# MK30D10 register map
Vendor: Freescale Semiconductor, Inc.; Series: Kinetis_K; File version: 1.6
CPU: CM4 r0p1, little endian, no MPU, no FPU, VTOR, 4 interrupt priority bits
Registers are 32-bit, read-write, reset 0x0 unless marked. A register's access mark holds for its fields unless they carry their own. Offsets are from the block's base; [hi:lo] are bit positions; {n}, {i} and the like mark numbered series; 'fields as' and 'values as' point back to an identical list.

## DAC0 — 12-Bit Digital-to-Analog Converter
Base 0x400CC000; register names take the prefix DAC0_
{0x0+2i} DAT{i}L (i=0..15) 8-bit — DAC Data Low Register
  [7:0] DATA0 — When the DAC buffer is not enabled, DATA[11:0] controls the output voltage based on the following formula: V out = V in * (1 + DACDAT0[11:0])/4096 When the DAC buffer is enabled, DATA is mapped to the 16-word buffer
{0x1+2i} DAT{i}H (i=0..15) 8-bit — DAC Data High Register
  [3:0] DATA1 — When the DAC Buffer is not enabled, DATA[11:0] controls the output voltage based on the following formula
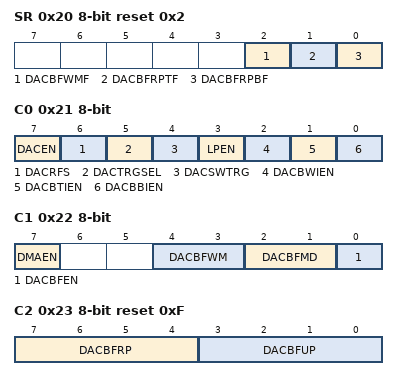
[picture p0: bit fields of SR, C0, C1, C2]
0x20 SR 8-bit reset 0x2 — DAC Status Register
  [2] DACBFWMF — DAC Buffer Watermark Flag
    0=The DAC buffer read pointer has not reached the watermark level; 1=The DAC buffer read pointer has reached the watermark level
  [1] DACBFRPTF — DAC Buffer Read Pointer Top Position Flag
    0=The DAC buffer read pointer is not zero; 1=The DAC buffer read pointer is zero
  [0] DACBFRPBF — DAC Buffer Read Pointer Bottom Position Flag
    0=The DAC buffer read pointer is not equal to C2[DACBFUP]; 1=The DAC buffer read pointer is equal to C2[DACBFUP]
0x21 C0 8-bit — DAC Control Register
  [7] DACEN — DAC Enable
    0=The DAC system is disabled; 1=The DAC system is enabled
  [6] DACRFS — DAC Reference Select
    0=The DAC selects DACREF_1 as the reference voltage; 1=The DAC selects DACREF_2 as the reference voltage
  [5] DACTRGSEL — DAC Trigger Select
    0=The DAC hardware trigger is selected; 1=The DAC software trigger is selected
  [4] DACSWTRG wo — DAC Software Trigger
    0=The DAC soft trigger is not valid; 1=The DAC soft trigger is valid
  [3] LPEN — DAC Low Power Control
    0=High-Power mode; 1=Low-Power mode
  [2] DACBWIEN — DAC Buffer Watermark Interrupt Enable
    0=The DAC buffer watermark interrupt is disabled; 1=The DAC buffer watermark interrupt is enabled
  [1] DACBTIEN — DAC Buffer Read Pointer Top Flag Interrupt Enable
    0=The DAC buffer read pointer top flag interrupt is disabled; 1=The DAC buffer read pointer top flag interrupt is enabled
  [0] DACBBIEN — DAC Buffer Read Pointer Bottom Flag Interrupt Enable
    0=The DAC buffer read pointer bottom flag interrupt is disabled; 1=The DAC buffer read pointer bottom flag interrupt is enabled
0x22 C1 8-bit — DAC Control Register 1
  [7] DMAEN — DMA Enable Select
    0=DMA is disabled; 1=DMA is enabled. When DMA is enabled, the DMA request will be generated by original interrupts. The interrupts will not be presented on this module at the same time.
  [4:3] DACBFWM — DAC Buffer Watermark Select
    0=1 word; 1=2 words; 2=3 words; 3=4 words
  [2:1] DACBFMD — DAC Buffer Work Mode Select
    0=Normal mode; 1=Swing mode; 2=One-Time Scan mode
  [0] DACBFEN — DAC Buffer Enable
    0=Buffer read pointer is disabled. The converted data is always the first word of the buffer.; 1=Buffer read pointer is enabled. The converted data is the word that the read pointer points to. It means converted data can be from any word of the buffer.
0x23 C2 8-bit reset 0xF — DAC Control Register 2
  [7:4] DACBFRP — DAC Buffer Read Pointer
  [3:0] DACBFUP — DAC Buffer Upper Limit

## DAC1 — 12-Bit Digital-to-Analog Converter
Base 0x400CD000; register names take the prefix DAC1_
Registers as DAC0.

## GPIOA — General Purpose Input/Output
Base 0x400FF000; register names take the prefix GPIOA_
0x00 PDOR — Port Data Output Register
  [31:0] PDO — Port Data Output
    0=Logic level 0 is driven on pin, provided pin is configured for general-purpose output; 1=Logic level 1 is driven on pin, provided pin is configured for general-purpose output
0x04 PSOR wo — Port Set Output Register
  [31:0] PTSO — Port Set Output
    0=Corresponding bit in PDORn does not change; 1=Corresponding bit in PDORn is set to logic 1
0x08 PCOR wo — Port Clear Output Register
  [31:0] PTCO — Port Clear Output
    0=Corresponding bit in PDORn does not change; 1=Corresponding bit in PDORn is cleared to logic 0
0x0C PTOR wo — Port Toggle Output Register
  [31:0] PTTO — Port Toggle Output
    0=Corresponding bit in PDORn does not change; 1=Corresponding bit in PDORn is set to the inverse of its existing logic state
0x10 PDIR ro — Port Data Input Register
  [31:0] PDI — Port Data Input
    0=Pin logic level is logic 0, or is not configured for use by digital function; 1=Pin logic level is logic 1
0x14 PDDR — Port Data Direction Register
  [31:0] PDD — Port Data Direction
    0=Pin is configured as general-purpose input, for the GPIO function; 1=Pin is configured as general-purpose output, for the GPIO function

## GPIOB — General Purpose Input/Output
Base 0x400FF040; register names take the prefix GPIOB_
Registers as GPIOA.

## GPIOC — General Purpose Input/Output
Base 0x400FF080; register names take the prefix GPIOC_
Registers as GPIOA.

## GPIOD — General Purpose Input/Output
Base 0x400FF0C0; register names take the prefix GPIOD_
Registers as GPIOA.

## GPIOE — General Purpose Input/Output
Base 0x400FF100; register names take the prefix GPIOE_
Registers as GPIOA.

## SysTick — System timer
Base 0xE000E010; register names take the prefix SYST_
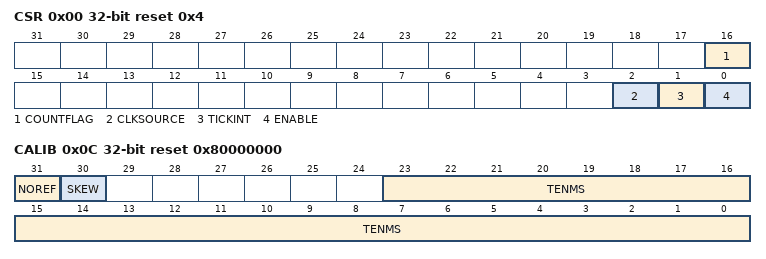
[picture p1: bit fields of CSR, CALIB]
0x00 CSR reset 0x4 — SysTick Control and Status Register
  [16] COUNTFLAG
  [2] CLKSOURCE
    0=external clock; 1=processor clock
  [1] TICKINT
    0=counting down to 0 does not assert the SysTick exception request; 1=counting down to 0 asserts the SysTick exception request
  [0] ENABLE
    0=counter disabled; 1=counter enabled
0x04 RVR — SysTick Reload Value Register
  [23:0] RELOAD — Value to load into the SysTick Current Value Register when the counter reaches 0
0x08 CVR — SysTick Current Value Register
  [23:0] CURRENT — Current value at the time the register is accessed
0x0C CALIB ro reset 0x80000000 — SysTick Calibration Value Register
  [31] NOREF
    0=The reference clock is provided; 1=The reference clock is not provided
  [30] SKEW
    0=10ms calibration value is exact; 1=10ms calibration value is inexact, because of the clock frequency
  [23:0] TENMS — Reload value to use for 10ms timing

## MCM — Core Platform Miscellaneous Control Module
Base 0xE0080000; register names take the prefix MCM_
0x08 PLASC 16-bit ro reset 0x1F — Crossbar Switch (AXBS) Slave Configuration
  [7:0] ASC — Each bit in the ASC field indicates whether there is a corresponding connection to the crossbar switch's slave input port.
    0=A bus slave connection to AXBS input port n is absent; 1=A bus slave connection to AXBS input port n is present
0x0A PLAMC 16-bit ro reset 0x3F — Crossbar Switch (AXBS) Master Configuration
  [7:0] AMC — Each bit in the AMC field indicates whether there is a corresponding connection to the AXBS master input port.
    0=A bus master connection to AXBS input port n is absent; 1=A bus master connection to AXBS input port n is present
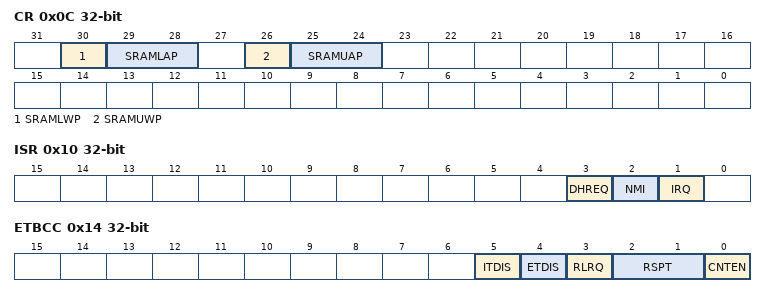
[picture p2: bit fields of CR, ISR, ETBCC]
0x0C CR — Control Register
  [30] SRAMLWP — SRAM_L Write Protect
  [29:28] SRAMLAP — SRAM_L arbitration priority
    0=Round robin; 1=Special round robin (favors SRAM backoor accesses over the processor); 2=Fixed priority. Processor has highest, backdoor has lowest; 3=Fixed priority. Backdoor has highest, processor has lowest
  [26] SRAMUWP — SRAM_U write protect
  [25:24] SRAMUAP — SRAM_U arbitration priority
    values as SRAMLAP
0x10 ISR — Interrupt Status Register
  [3] DHREQ ro — Debug Halt Request Indicator
    0=No debug halt request; 1=Debug halt request initiated
  [2] NMI — Non-maskable Interrupt Pending
    0=No pending NMI; 1=Due to the ETB counter expiring, an NMI is pending
  [1] IRQ — Normal Interrupt Pending
    0=No pending interrupt; 1=Due to the ETB counter expiring, a normal interrupt is pending
0x14 ETBCC — ETB Counter Control register
  [5] ITDIS — ITM-To-TPIU Disable
    0=ITM-to-TPIU trace path enabled; 1=ITM-to-TPIU trace path disabled
  [4] ETDIS — ETM-To-TPIU Disable
    0=ETM-to-TPIU trace path enabled; 1=ETM-to-TPIU trace path disabled
  [3] RLRQ — Reload Request
    0=No effect; 1=Clears pending debug halt, NMI, or IRQ interrupt requests
  [2:1] RSPT — Response Type
    0=No response when the ETB count expires; 1=Generate a normal interrupt when the ETB count expires; 2=Generate an NMI when the ETB count expires; 3=Generate a debug halt when the ETB count expires
  [0] CNTEN — Counter Enable
    0=ETB counter disabled; 1=ETB counter enabled
0x18 ETBRL — ETB Reload register
  [10:0] RELOAD — Byte Count Reload Value
0x1C ETBCNT ro — ETB Counter Value register
  [10:0] COUNTER — Byte Count Counter Value
0x30 PID — Process ID register
  [7:0] PID — M0_PID And M1_PID For MPU

## Notices in the file
Redistribution and use in source and binary forms, with or without modification,
are permitted provided that the following conditions are met:
o Redistributions of source code must retain the above copyright notice, this list
of conditions and the following disclaimer.
o Redistributions in binary form must reproduce the above copyright notice, this
list of conditions and the following disclaimer in the documentation and/or
other materials provided with the distribution.
o Neither the name of Freescale Semiconductor, Inc. nor the names of its
contributors may be used to endorse or promote products derived from this
software without specific prior written permission.
THIS SOFTWARE IS PROVIDED BY THE COPYRIGHT HOLDERS AND CONTRIBUTORS "AS IS" AND
ANY EXPRESS OR IMPLIED WARRANTIES, INCLUDING, BUT NOT LIMITED TO, THE IMPLIED
WARRANTIES OF MERCHANTABILITY AND FITNESS FOR A PARTICULAR PURPOSE ARE
DISCLAIMED. IN NO EVENT SHALL THE COPYRIGHT HOLDER OR CONTRIBUTORS BE LIABLE FOR
ANY DIRECT, INDIRECT, INCIDENTAL, SPECIAL, EXEMPLARY, OR CONSEQUENTIAL DAMAGES
(INCLUDING, BUT NOT LIMITED TO, PROCUREMENT OF SUBSTITUTE GOODS OR SERVICES;
LOSS OF USE, DATA, OR PROFITS; OR BUSINESS INTERRUPTION) HOWEVER CAUSED AND ON
ANY THEORY OF LIABILITY, WHETHER IN CONTRACT, STRICT LIABILITY, OR TORT
(INCLUDING NEGLIGENCE OR OTHERWISE) ARISING IN ANY WAY OUT OF THE USE OF THIS
SOFTWARE, EVEN IF ADVISED OF THE POSSIBILITY OF SUCH DAMAGE.
